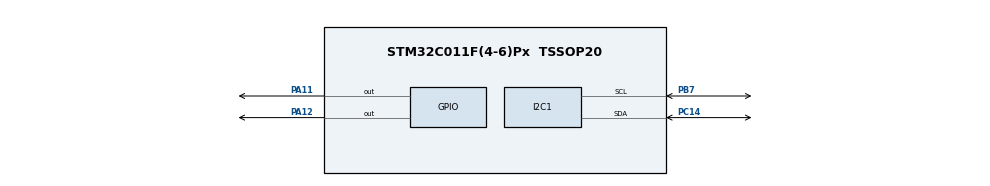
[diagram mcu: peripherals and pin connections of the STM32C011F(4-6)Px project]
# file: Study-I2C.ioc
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I2C1.DualAddressMode=I2C_DUALADDRESS_ENABLE
I2C1.GeneralCallMode=I2C_GENERALCALL_ENABLE
I2C1.OwnAddress=0x45
I2C1.OwnAddress2=0x46
I2C1.Timing=0x00402D41
Mcu.Family=STM32C0
Mcu.Name=STM32C011F(4-6)Px
Mcu.Package=TSSOP20
NVIC.I2C1_IRQn=true\:0\:0\:false\:false\:true\:true\:true\:true
PA11\ [PA9].Signal=GPIO_Output
PA12\ [PA10].Signal=GPIO_Output
PB7.Mode=I2C
PB7.Signal=I2C1_SCL
PC14-OSCX_IN\ (PC14).Mode=I2C
PC14-OSCX_IN\ (PC14).Signal=I2C1_SDA
ProjectManager.HeapSize=0x200
ProjectManager.StackSize=0x400
ProjectManager.TargetToolchain=STM32CubeIDE
RCC.ADCFreq_Value=12000000
RCC.AHBFreq_Value=12000000
RCC.CortexFreq_Value=12000000
RCC.EXTERNAL_CLOCK_VALUE=12288000
RCC.HCLKFreq_Value=12000000
RCC.HSE_VALUE=8000000
RCC.HSI_VALUE=48000000
RCC.LSE_VALUE=32768
RCC.SYSCLKFreq_VALUE=12000000
board=custom

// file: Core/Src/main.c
/* USER CODE BEGIN Header */
/**
  ******************************************************************************
  * @file           : main.c
  * @brief          : Main program body
  ******************************************************************************
  * @attention
  *
  * Copyright (c) 2024 STMicroelectronics.
  * All rights reserved.
  *
  * This software is licensed under terms that can be found in the LICENSE file
  * in the root directory of this software component.
  * If no LICENSE file comes with this software, it is provided AS-IS.
  *
  ******************************************************************************
  */
/* USER CODE END Header */
#include "main.h"

I2C_HandleTypeDef hi2c1;

void SystemClock_Config(void);
static void MX_GPIO_Init(void);
static void MX_I2C1_Init(void);

int main(void)
{

  /* MCU Configuration--------------------------------------------------------*/

  /* Reset of all peripherals, Initializes the Flash interface and the Systick. */
  HAL_Init();

  /* Configure the system clock */
  SystemClock_Config();

  /* Initialize all configured peripherals */
  MX_GPIO_Init();
  MX_I2C1_Init();
  /* USER CODE BEGIN 2 */

  // マスターからの受信リクエストを有効化する
  if ( HAL_I2C_EnableListen_IT(&hi2c1) != HAL_OK ) {
	  Error_Handler();
  }

  /* USER CODE END 2 */

  /* Infinite loop */
  /* USER CODE BEGIN WHILE */
  while (1)
  {
	// Lチカ
	HAL_GPIO_TogglePin(GPIOA, GPIO_PIN_12); // PA12
	HAL_Delay(200);
    /* USER CODE END WHILE */

  }
}

void SystemClock_Config(void)
{
  RCC_OscInitTypeDef RCC_OscInitStruct = {0};
  RCC_ClkInitTypeDef RCC_ClkInitStruct = {0};

  /** Initializes the RCC Oscillators according to the specified parameters
  * in the RCC_OscInitTypeDef structure.
  */
  RCC_OscInitStruct.OscillatorType = RCC_OSCILLATORTYPE_HSI;
  RCC_OscInitStruct.HSIState = RCC_HSI_ON;
  RCC_OscInitStruct.HSIDiv = RCC_HSI_DIV4;
  RCC_OscInitStruct.HSICalibrationValue = RCC_HSICALIBRATION_DEFAULT;
  if (HAL_RCC_OscConfig(&RCC_OscInitStruct) != HAL_OK)
  {
    Error_Handler();
  }

  /** Initializes the CPU, AHB and APB buses clocks
  */
  RCC_ClkInitStruct.ClockType = RCC_CLOCKTYPE_HCLK|RCC_CLOCKTYPE_SYSCLK
                              |RCC_CLOCKTYPE_PCLK1;
  RCC_ClkInitStruct.SYSCLKSource = RCC_SYSCLKSOURCE_HSI;
  RCC_ClkInitStruct.SYSCLKDivider = RCC_SYSCLK_DIV1;
  RCC_ClkInitStruct.AHBCLKDivider = RCC_HCLK_DIV1;
  RCC_ClkInitStruct.APB1CLKDivider = RCC_APB1_DIV1;

  if (HAL_RCC_ClockConfig(&RCC_ClkInitStruct, FLASH_LATENCY_0) != HAL_OK)
  {
    Error_Handler();
  }
}

static void MX_I2C1_Init(void)
{

  hi2c1.Instance = I2C1;
  hi2c1.Init.Timing = 0x00402D41;
  hi2c1.Init.OwnAddress1 = 138;
  hi2c1.Init.AddressingMode = I2C_ADDRESSINGMODE_7BIT;
  hi2c1.Init.DualAddressMode = I2C_DUALADDRESS_ENABLE;
  hi2c1.Init.OwnAddress2 = 140;
  hi2c1.Init.OwnAddress2Masks = I2C_OA2_NOMASK;
  hi2c1.Init.GeneralCallMode = I2C_GENERALCALL_ENABLE;
  hi2c1.Init.NoStretchMode = I2C_NOSTRETCH_DISABLE;
  if (HAL_I2C_Init(&hi2c1) != HAL_OK)
  {
    Error_Handler();
  }

  /** Configure Analogue filter
  */
  if (HAL_I2CEx_ConfigAnalogFilter(&hi2c1, I2C_ANALOGFILTER_ENABLE) != HAL_OK)
  {
    Error_Handler();
  }

  /** Configure Digital filter
  */
  if (HAL_I2CEx_ConfigDigitalFilter(&hi2c1, 0) != HAL_OK)
  {
    Error_Handler();
  }

}

static void MX_GPIO_Init(void)
{
  GPIO_InitTypeDef GPIO_InitStruct = {0};

  /* GPIO Ports Clock Enable */
  __HAL_RCC_GPIOB_CLK_ENABLE();
  __HAL_RCC_GPIOC_CLK_ENABLE();
  __HAL_RCC_GPIOA_CLK_ENABLE();

  /*Configure GPIO pin Output Level */
  HAL_GPIO_WritePin(GPIOA, GPIO_PIN_11|GPIO_PIN_12, GPIO_PIN_RESET);

  /*Configure GPIO pins : PA11 PA12 */
  GPIO_InitStruct.Pin = GPIO_PIN_11|GPIO_PIN_12;
  GPIO_InitStruct.Mode = GPIO_MODE_OUTPUT_PP;
  GPIO_InitStruct.Pull = GPIO_NOPULL;
  GPIO_InitStruct.Speed = GPIO_SPEED_FREQ_LOW;
  HAL_GPIO_Init(GPIOA, &GPIO_InitStruct);

}

void Error_Handler(void)
{
  __disable_irq();
  while (1)
  {
  }
}
